# EFR32BG13P532F512GM32 register map
File version: 5.8.2
CPU: CM4 r0p1, little endian, MPU, FPU, 3 interrupt priority bits
Registers are 32-bit, read-write, reset 0x0 unless marked. A register's access mark holds for its fields unless they carry their own. Offsets are from the block's base; [hi:lo] are bit positions.

## NVIC_ICER — Nested vectored interrupt controller
Base 0xE000E180
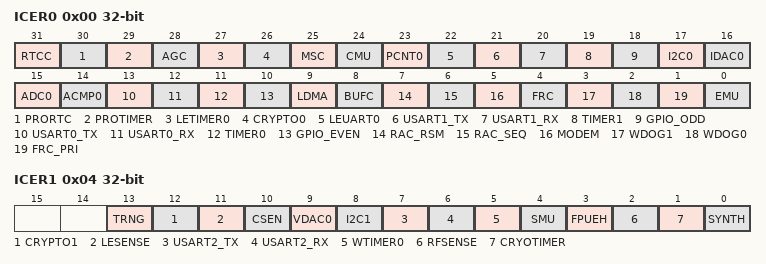
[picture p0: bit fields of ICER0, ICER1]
0x00 ICER0 — Interrupt Clear Enable Register 0
  [31] RTCC — RTCC Interrupt
  [30] PRORTC — PRORTC Interrupt
  [29] PROTIMER — PROTIMER Interrupt
  [28] AGC — AGC Interrupt
  [27] LETIMER0 — LETIMER0 Interrupt
  [26] CRYPTO0 — CRYPTO0 Interrupt
  [25] MSC — MSC Interrupt
  [24] CMU — CMU Interrupt
  [23] PCNT0 — PCNT0 Interrupt
  [22] LEUART0 — LEUART0 Interrupt
  [21] USART1_TX — USART1_TX Interrupt
  [20] USART1_RX — USART1_RX Interrupt
  [19] TIMER1 — TIMER1 Interrupt
  [18] GPIO_ODD — GPIO_ODD Interrupt
  [17] I2C0 — I2C0 Interrupt
  [16] IDAC0 — IDAC0 Interrupt
  [15] ADC0 — ADC0 Interrupt
  [14] ACMP0 — ACMP0 Interrupt
  [13] USART0_TX — USART0_TX Interrupt
  [12] USART0_RX — USART0_RX Interrupt
  [11] TIMER0 — TIMER0 Interrupt
  [10] GPIO_EVEN — GPIO_EVEN Interrupt
  [9] LDMA — LDMA Interrupt
  [8] BUFC — BUFC Interrupt
  [7] RAC_RSM — RAC_RSM Interrupt
  [6] RAC_SEQ — RAC_SEQ Interrupt
  [5] MODEM — MODEM Interrupt
  [4] FRC — FRC Interrupt
  [3] WDOG1 — WDOG1 Interrupt
  [2] WDOG0 — WDOG0 Interrupt
  [1] FRC_PRI — FRC_PRI Interrupt
  [0] EMU — EMU Interrupt
0x04 ICER1 — Interrupt Clear Enable Register 1
  [13] TRNG — TRNG Interrupt
  [12] CRYPTO1 — CRYPTO1 Interrupt
  [11] LESENSE — LESENSE Interrupt
  [10] CSEN — CSEN Interrupt
  [9] VDAC0 — VDAC0 Interrupt
  [8] I2C1 — I2C1 Interrupt
  [7] USART2_TX — USART2_TX Interrupt
  [6] USART2_RX — USART2_RX Interrupt
  [5] WTIMER0 — WTIMER0 Interrupt
  [4] SMU — SMU Interrupt
  [3] FPUEH — FPUEH Interrupt
  [2] RFSENSE — RFSENSE Interrupt
  [1] CRYOTIMER — CRYOTIMER Interrupt
  [0] SYNTH — SYNTH Interrupt

## NVIC_ISPR — Nested vectored interrupt controller
Base 0xE000E200
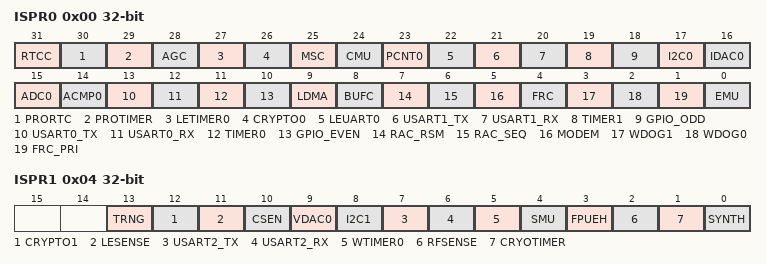
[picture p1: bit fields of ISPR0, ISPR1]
0x00 ISPR0 — Interrupt Set Pending Register 0
  [31] RTCC — RTCC Interrupt
  [30] PRORTC — PRORTC Interrupt
  [29] PROTIMER — PROTIMER Interrupt
  [28] AGC — AGC Interrupt
  [27] LETIMER0 — LETIMER0 Interrupt
  [26] CRYPTO0 — CRYPTO0 Interrupt
  [25] MSC — MSC Interrupt
  [24] CMU — CMU Interrupt
  [23] PCNT0 — PCNT0 Interrupt
  [22] LEUART0 — LEUART0 Interrupt
  [21] USART1_TX — USART1_TX Interrupt
  [20] USART1_RX — USART1_RX Interrupt
  [19] TIMER1 — TIMER1 Interrupt
  [18] GPIO_ODD — GPIO_ODD Interrupt
  [17] I2C0 — I2C0 Interrupt
  [16] IDAC0 — IDAC0 Interrupt
  [15] ADC0 — ADC0 Interrupt
  [14] ACMP0 — ACMP0 Interrupt
  [13] USART0_TX — USART0_TX Interrupt
  [12] USART0_RX — USART0_RX Interrupt
  [11] TIMER0 — TIMER0 Interrupt
  [10] GPIO_EVEN — GPIO_EVEN Interrupt
  [9] LDMA — LDMA Interrupt
  [8] BUFC — BUFC Interrupt
  [7] RAC_RSM — RAC_RSM Interrupt
  [6] RAC_SEQ — RAC_SEQ Interrupt
  [5] MODEM — MODEM Interrupt
  [4] FRC — FRC Interrupt
  [3] WDOG1 — WDOG1 Interrupt
  [2] WDOG0 — WDOG0 Interrupt
  [1] FRC_PRI — FRC_PRI Interrupt
  [0] EMU — EMU Interrupt
0x04 ISPR1 — Interrupt Set Pending Register 1
  [13] TRNG — TRNG Interrupt
  [12] CRYPTO1 — CRYPTO1 Interrupt
  [11] LESENSE — LESENSE Interrupt
  [10] CSEN — CSEN Interrupt
  [9] VDAC0 — VDAC0 Interrupt
  [8] I2C1 — I2C1 Interrupt
  [7] USART2_TX — USART2_TX Interrupt
  [6] USART2_RX — USART2_RX Interrupt
  [5] WTIMER0 — WTIMER0 Interrupt
  [4] SMU — SMU Interrupt
  [3] FPUEH — FPUEH Interrupt
  [2] RFSENSE — RFSENSE Interrupt
  [1] CRYOTIMER — CRYOTIMER Interrupt
  [0] SYNTH — SYNTH Interrupt

## NVIC_ICPR — Nested vectored interrupt controller
Base 0xE000E280
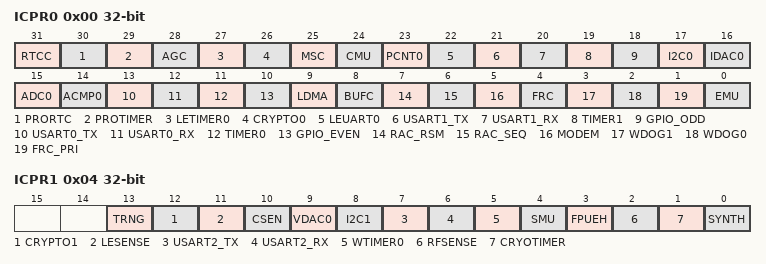
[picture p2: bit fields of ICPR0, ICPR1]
0x00 ICPR0 — Interrupt Clear Pending Register 0
  [31] RTCC — RTCC Interrupt
  [30] PRORTC — PRORTC Interrupt
  [29] PROTIMER — PROTIMER Interrupt
  [28] AGC — AGC Interrupt
  [27] LETIMER0 — LETIMER0 Interrupt
  [26] CRYPTO0 — CRYPTO0 Interrupt
  [25] MSC — MSC Interrupt
  [24] CMU — CMU Interrupt
  [23] PCNT0 — PCNT0 Interrupt
  [22] LEUART0 — LEUART0 Interrupt
  [21] USART1_TX — USART1_TX Interrupt
  [20] USART1_RX — USART1_RX Interrupt
  [19] TIMER1 — TIMER1 Interrupt
  [18] GPIO_ODD — GPIO_ODD Interrupt
  [17] I2C0 — I2C0 Interrupt
  [16] IDAC0 — IDAC0 Interrupt
  [15] ADC0 — ADC0 Interrupt
  [14] ACMP0 — ACMP0 Interrupt
  [13] USART0_TX — USART0_TX Interrupt
  [12] USART0_RX — USART0_RX Interrupt
  [11] TIMER0 — TIMER0 Interrupt
  [10] GPIO_EVEN — GPIO_EVEN Interrupt
  [9] LDMA — LDMA Interrupt
  [8] BUFC — BUFC Interrupt
  [7] RAC_RSM — RAC_RSM Interrupt
  [6] RAC_SEQ — RAC_SEQ Interrupt
  [5] MODEM — MODEM Interrupt
  [4] FRC — FRC Interrupt
  [3] WDOG1 — WDOG1 Interrupt
  [2] WDOG0 — WDOG0 Interrupt
  [1] FRC_PRI — FRC_PRI Interrupt
  [0] EMU — EMU Interrupt
0x04 ICPR1 — Interrupt Clear Pending Register 1
  [13] TRNG — TRNG Interrupt
  [12] CRYPTO1 — CRYPTO1 Interrupt
  [11] LESENSE — LESENSE Interrupt
  [10] CSEN — CSEN Interrupt
  [9] VDAC0 — VDAC0 Interrupt
  [8] I2C1 — I2C1 Interrupt
  [7] USART2_TX — USART2_TX Interrupt
  [6] USART2_RX — USART2_RX Interrupt
  [5] WTIMER0 — WTIMER0 Interrupt
  [4] SMU — SMU Interrupt
  [3] FPUEH — FPUEH Interrupt
  [2] RFSENSE — RFSENSE Interrupt
  [1] CRYOTIMER — CRYOTIMER Interrupt
  [0] SYNTH — SYNTH Interrupt
